# LFD2NX_40 register map
Vendor: Latticsemi.com; Series: LFD2NX; File version: 1.0
soc_gpio2
Registers are 32-bit, read-write, reset 0x0 unless marked. A register's access mark holds for its fields unless they carry their own. Offsets are from the block's base; lines under a group give offsets from that group; [hi:lo] are bit positions; {n}, {i} and the like mark numbered series; 'fields as' and 'values as' point back to an identical list; <NAME> marks a mode.

## Memory map
0x00000000 system0_inst size 0x8000
0x00008000 gpio2_inst size 0x400
0x40000000 gpio0_inst size 0x400
0x4000A000 uart0_inst size 0x400
0xFFFF0000 cpu0_inst size 0x800

## cpu0_inst
Base 0xFFFF0000
0x00 PIC_STATUS 2-bit — Interrupt Status Register
  [1:0] status — Interrupt Status
0x04 PIC_ENABLE 2-bit — Interrupt Enable Register
  [1:0] enable — Interrupt Enable
0x08 PIC_SET 2-bit wo — Interrupt Set Register
  [1:0] set — Interrupt Set
0x0C PIC_POL 2-bit — Interrupt Polarity Register
  [1:0] pol — Interrupt Polarity
0x400 TIMER_CNT_L — Timer Counter Lower Register
  [31:0] cnt_l — Lower 32 bits of 64-bit timer counter register
0x404 TIMER_CNT_H — Timer Counter Higher Register
  [31:0] cnt_h — Higher 32 bits of 64-bit timer counter register
0x410 TIMER_CMP_L — Timer Compare Lower Register
  [31:0] cmp_l — Lower 32 bits of 64-bit timer compare register
0x414 TIMER_CMP_H — Timer Compare Higher Register
  [31:0] cmp_h — Higher 32 bits of 64-bit timer compare register

## gpio0_inst
Base 0x40000000
0x00 RD_DATA_REG ro — Read Data Register
  [7:0] rd_data — Read actual values of GPIO's
0x04 WR_DATA_REG — Write Data Register
  [7:0] wr_data — Write GPIO output register
0x08 SET_DATA_REG wo — Set Data Register
  [7:0] set_data — Set GPIO output register
0x0C CLEAR_DATA_REG wo — Clear Data Register
  [7:0] clear_data — Clear GPIO output register
0x10 DIRECTION_REG — Direction Register
  [7:0] direction_reg — GPIO Direction register
0x14 INT_TYPE_REG — Interrupt Type Register
  [7:0] int_type — Interrupt Type Cofiguration Register, 1-Edge, 0-Level
0x18 INT_METHOD_REG — Interrupt Method Register
  [7:0] int_method — Interrupt Method Register, if Interrupt Type is Edge` 1-Rising edge 0-faling edge, if Interrupt Type is Level` 1-High level, 0-Low level
0x1C INT_STATUS_REG — Interrupt Status Register
  [7:0] int_status — Interrupt Status Register, indicates interrupt status
0x20 INT_ENABLE_REG — Interrupt Enable Register
  [7:0] Int_enable — Interrupt Enable Register, enables appropriate channel interrupt
0x24 INT_SET_REG wo — Interrupt Set Register
  [7:0] int_set — Interrupt Set Register, user can generate interrupt by writing '1' to the corresponding bit of this register

## gpio2_inst
Base 0x00008000
0x00 RD_DATA_REG ro — Read Data Register
  [31:0] rd_data — Read actual values of GPIO's
0x04 WR_DATA_REG — Write Data Register
  [31:0] wr_data — Write GPIO output register
0x08 SET_DATA_REG wo — Set Data Register
  [31:0] set_data — Set GPIO output register
0x0C CLEAR_DATA_REG wo — Clear Data Register
  [31:0] clear_data — Clear GPIO output register
0x10 DIRECTION_REG — Direction Register
  [31:0] direction_reg — GPIO Direction register
0x14 INT_TYPE_REG — Interrupt Type Register
  [31:0] int_type — Interrupt Type Cofiguration Register, 1-Edge, 0-Level
0x18 INT_METHOD_REG — Interrupt Method Register
  [31:0] int_method — Interrupt Method Register, if Interrupt Type is Edge` 1-Rising edge 0-faling edge, if Interrupt Type is Level` 1-High level, 0-Low level
0x1C INT_STATUS_REG — Interrupt Status Register
  [31:0] int_status — Interrupt Status Register, indicates interrupt status
0x20 INT_ENABLE_REG — Interrupt Enable Register
  [31:0] Int_enable — Interrupt Enable Register, enables appropriate channel interrupt
0x24 INT_SET_REG wo — Interrupt Set Register
  [31:0] int_set — Interrupt Set Register, user can generate interrupt by writing '1' to the corresponding bit of this register

## uart0_inst
Base 0x4000A000
0x00 THR wo — Transmitter Holding Register is the interface to the Transmitter Buffer/FIFO (XMIT FIFO).
  [7:0] XMIT_FIFO — Write access to this field pushes data to XMIT FIFO
0x00 RBR ro — Receive Buffer Register is the interface to the Receiver Buffer/FIFO (RCVR FIFO).
  [7:0] RCVR_FIFO — Read access to this field pops data from RCVR FIFO
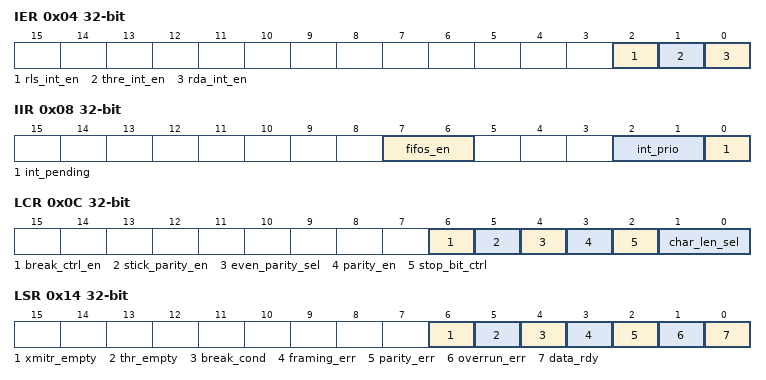
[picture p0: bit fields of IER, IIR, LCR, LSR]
0x04 IER — Interrupt Enable Register enables the four types of UART interrupts.
  [2] rls_int_en — Receiver Line Status Interrupt Enable. 0-> Interrupt is disabled. 1-> Interrupt is enabled.
  [1] thre_int_en — Transmitter Holding Register Empty Interrupt Enable. 0-> Interrupt is disabled. 1-> Interrupt is enabled.
  [0] rda_int_en — Received Data Available Interrupt Enable. 0-> Interrupt is disabled. 1-> Interrupt is enabled.
0x08 IIR ro — Interrupt Identification Register determines the asserted interrupt based on priority.
  [7:6] fifos_en — FIFO mode - Fixed to logic 2'b11. Non-FIFO mode - fixed to 2'b00.
  [2:1] int_prio — 2'b11 -> Receiver Line Status Interrupt. 2'b10 -> Received Data Available Interrupt. 2'b01 -> Transmitter Holding Register Empty Interrupt. 2'b00 -> MODEM Status Interrupt.
  [0] int_pending — 0 -> Interrupt is pending according to int_prio and timeout_int. 1 -> No pending interrupt.
0x0C LCR — Line Control Register configures character length, number stop bits and parity bit.
  [6] break_ctrl_en — Break Control Enable. 0 -> Break control is disabled. 1 -> Break control is enabled.
  [5] stick_parity_en — Stick Parity Enable. 0 -> Stick parity is disabled. 1 -> Stick parity is enabled.
  [4] even_parity_sel — Even Parity Select. 0 -> Odd parity. 1 -> Even Parity.
  [3] parity_en — Parity Enable. 0-> Parity generation and checking is disabled. 1-> Parity generation and checking is enabled.
  [2] stop_bit_ctrl — 0 -> One stop bit is generated in the transmitted data. 1 -> Two stop bits are generated.
  [1:0] char_len_sel — 2'b00 -> 5 bits. 2'b01 -> 6 bits. 2'b10 -> 7 bits. 2'b11 -> 8 bits.
0x14 LSR ro — Line Status Register
  [6] xmitr_empty — Transmitter Empty bit asserts when both XMIT FIFO and Transmitter Shift Register are empty.
  [5] thr_empty — THR Empty bit asserts when XMIT FIFO is empty.
  [4] break_cond — Break condition indicator asserts when rxd_i is held low for longer than full RX time.
  [3] framing_err — Framing Error Indicator asserts when received data does not have a valid stop bit.
  [2] parity_err — Parity Error Indicator asserts when parity error occurs.
  [1] overrun_err — Overrun Error Indicator asserts when RCVR FIFO is full and the next character has been fully received.
  [0] data_rdy — Data Ready Indicator asserts when RCVR FIFO has data.
0x20 DLAB_LSB — Divisor Latch Register LSB
  [7:0] divisor_lsb — The lower byte of the Divisor Latch Register.
0x24 DLAB_MSB — Divisor Latch Register MSB
  [7:0] divisor_msb — The upper byte of the Divisor Latch Register.
